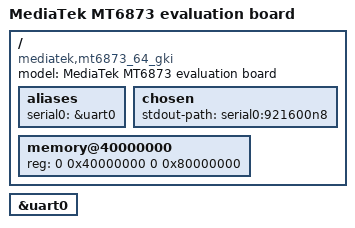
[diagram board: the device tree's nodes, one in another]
// SPDX-License-Identifier: (GPL-2.0 OR MIT)
/*
 * Copyright (C) 2020 MediaTek Inc.
 * Author: Chun-Hung Wu <chun-hung.wu@mediatek.com>
 */
/dts-v1/;
#include "mt6873.dtsi"

/ {
	model = "MediaTek MT6873 evaluation board";
	compatible = "mediatek,mt6873_64_gki", "mediatek,mt6873";

	aliases {
		serial0 = &uart0;
	};

	chosen {
		stdout-path = "serial0:921600n8";
	};

	memory@40000000 {
		device_type = "memory";
		reg = <0 0x40000000 0 0x80000000>;
	};
};

&uart0 {
	status = "okay";
};
